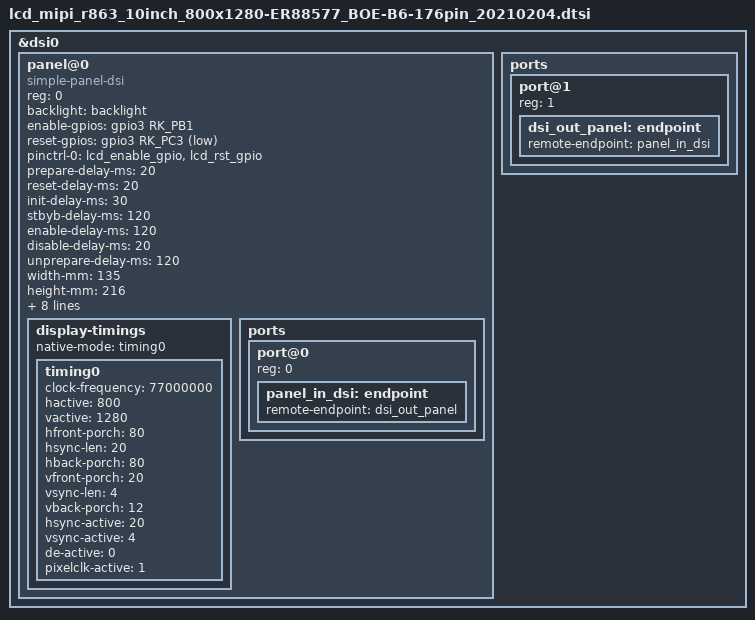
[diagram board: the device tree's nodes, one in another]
/*
* incar mipi lcd
*/
&dsi0 {
	status = "okay";
	//rockchip,lane-rate = <1000>;
	panel@0 {
		compatible = "simple-panel-dsi";
		reg = <0>;
		backlight = <&backlight>;
		//power-supply=<&vcc_3v3>;
		enable-gpios = <&gpio3 RK_PB1 GPIO_ACTIVE_HIGH>;
		//stbyb-gpios = <&gpio0 RK_PC0 GPIO_ACTIVE_LOW>;
		reset-gpios = <&gpio3 RK_PC3 GPIO_ACTIVE_LOW>;
		pinctrl-names = "default";
		pinctrl-0 = <&lcd_enable_gpio>, <&lcd_rst_gpio>;

		prepare-delay-ms = <20>;
		reset-delay-ms = <20>;
		init-delay-ms = <30>;
		stbyb-delay-ms = <120>;
		enable-delay-ms = <120>;
		disable-delay-ms = <20>;
		unprepare-delay-ms = <120>;

		width-mm = <135>;
		height-mm = <216>;

		dsi,flags = <(MIPI_DSI_MODE_VIDEO | MIPI_DSI_MODE_VIDEO_BURST |
			      MIPI_DSI_MODE_LPM | MIPI_DSI_MODE_EOT_PACKET)>;
		dsi,format = <MIPI_DSI_FMT_RGB888>;
		dsi,lanes = <4>;

		panel-init-sequence = [

39 00 03 E0 AB BA
39 00 03 E1 BA AB
15 00 02 B0 00
39 00 05 B1 10 01 47 FF
39 00 07 B2 0c 14 04 50 50 14
39 00 04 B3 56 D3 00
39 00 04 B4 22 30 04
15 00 02 B5 00
39 00 08 B6 B0 00 00 10 00 10 00
39 00 09 B7 0E 00 FF 08 08 FF FF 00
39 00 08 B8 05 12 29 49 48 00 00
39 00 27 B9 7c 5f 4d 40 3c 2d 32 1d 37 37 39 59 49 53 46 43 36 25 06 7c 5f 4d 40 3c 2d 32 1d 37 37 39 59 49 53 46 43 36 25 06 
39 00 09 BA 00 00 00 44 24 00 00 00 
39 00 04 BB 76 00 00 
39 00 03 BC 00 00 
39 00 06 BD FF 00 00 00 00 
15 00 02 BE 00 
39 00 11 C0 76 54 12 34 33 33 44 44 10 04 90 04 0F 00 00 00 
39 00 0B C1 53 94 02 8D 10 04 90 04 54 00 
39 00 0D C2 37 0B 0E 8B 0E 11 22 33 44 82 18 00 
39 00 17 C3 9C 5C 05 05 07 07 1D 1D 23 02 22 22 02 0F 0F 0D 0D 13 13 11 11 00 
39 00 17 C4 1C 1C 04 04 06 06 1D 1D 23 02 22 22 02 0E 0E 0C 0C 12 12 10 10 00 
39 00 04 C5 E8 85 76 
39 00 03 C6 21 21 
39 00 17 C7 41 01 0D 11 09 15 19 4F 10 D7 CF 19 1B 1D 03 02 25 30 00 03 FF 00 
39 00 07 C8 61 00 02 43 54 16 
39 00 06 C9 A1 22 FF C4 23 
39 00 03 CA 4B 43 
39 00 05 CC 2E 02 04 08 
39 00 09 CD 0E 4B 4B 20 19 6B 06 83 
39 00 04 D0 27 10 80 
39 00 05 D1 00 0D FF 0F 
39 00 05 D2 E3 2B 38 00 // 4 LAN
39 00 0C D4 00 01 00 0E 04 44 08 10 00 07 00 
15 00 02 D5 00 
39 00 03 D6 00 00 
39 00 05 D7 00 00 00 00 
39 00 04 E4 08 55 03 
39 00 09 E6 00 01 FF FF FF FF FF FF 
39 00 04 E7 00 00 00 
39 00 08 E8 D5 FF FF FF 00 00 00 
15 00 02 E9 FF 
39 00 06 F0 12 03 20 00 FF 
39 00 1B F1 A6 C8 EA E6 E4 CC E4 BE F0 B2 AA C7 FF 66 98 E3 87 C8 99 C8 8C BE 96 91 8F FF 
15 00 02 F3 03 
39 00 1B F4 FF FE FC FA F8 F4 F0 E8 E0 D0 C0 A0 80 7F 5F 3F 2F 1F 17 0F 0B 07 05 03 01 00 
39 00 1B F5 FF FE FC FA F8 F4 F0 E8 E0 D0 C0 A0 80 7F 5F 3F 2F 1F 17 0F 0B 07 05 03 01 00 
39 00 1B F6 FF FE FC FA F8 F4 F0 E8 E0 D0 C0 A0 80 7F 5F 3F 2F 1F 17 0F 0B 07 05 03 01 00 
39 00 08 F7 00 00 00 00 00 00 00 
39 00 08 F8 00 00 00 00 00 00 00 
39 00 08 F9 00 00 00 00 00 00 00 
39 00 1A FA 00 84 12 21 48 48 21 12 84 69 69 5A A5 96 96 A5 5A B7 DE ED 7B 7B ED DE B7 
39 00 18 FB 00 12 0F FF FF FF 00 38 40 08 70 0B 40 19 50 21 C0 27 60 2D 00 00 0F 
05 78 01 11 
05 14 01 29 

			 
		];

		panel-exit-sequence = [
			05 14 01 28
			05 78 01 10
		];

		display-timings {
			native-mode = <&timing0>;
			timing0: timing0 {
				clock-frequency = <77000000>;
				hactive = <800>;
				vactive = <1280>;
				hfront-porch = <80>;
				hsync-len = <20>;
				hback-porch = <80>;
				vfront-porch = <20>;
				vsync-len = <4>;
				vback-porch = <12>;
				hsync-active = <20>;
				vsync-active = <4>;
				de-active = <0>;
				pixelclk-active = <1>;
			};
		};
		ports {
			#address-cells = <1>;
			#size-cells = <0>;

			port@0 {
				reg = <0>;
				panel_in_dsi: endpoint {
					remote-endpoint = <&dsi_out_panel>;
				};
			};
		};
	};

	ports {
		#address-cells = <1>;
		#size-cells = <0>;

		port@1 {
			reg = <1>;
			dsi_out_panel: endpoint {
				remote-endpoint = <&panel_in_dsi>;
			};
		};
	};
};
